# R7FA8M1AH register map
Vendor: Renesas; Series: RA8; File version: 1.2
CPU: CM85 r0p0, little endian, MPU, FPU, VTOR, 4 interrupt priority bits
Registers are 32-bit, read-write, reset 0x0 unless marked. A register's access mark holds for its fields unless they carry their own. Offsets are from the block's base; [hi:lo] are bit positions; {n}, {i} and the like mark numbered series; 'fields as' and 'values as' point back to an identical list.

## SPI0 — Serial Peripheral Interface 0
Base 0x4035C000
Same registers: SPI1 0x4035C100, SPI0_NS 0x5035C000, SPI1_NS 0x5035C100
0x00 SPDR — RSPI Data Register
  [31:0] SPD — SPDR is the interface with the buffers that hold data for transmission and reception by the SPI.When accessing in word (SPDCR.SPBYT=0 and SPDCR.SPLW=1), access SPDR.
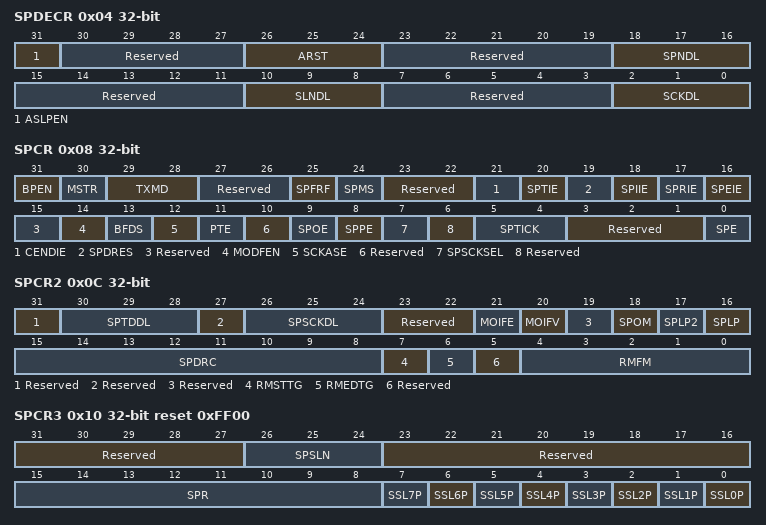
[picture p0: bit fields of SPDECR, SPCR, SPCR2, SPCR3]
0x04 SPDECR — RSPI Delay Control Register
  [31] ASLPEN — Receive sampling timing loopback adjustment function selection bit(Private)
    0=Receive sampling timing loopback adjustment function enabled; 1=Receive sampling timing loopback adjustment function disabled
  [30:27] Reserved — These bits are read as 0000. The write value should be 0000.
  [26:24] ARST — Adjust receive sampling by delaying 0 to 4 TCLK from the center of bit.
    0=0 TCLK delay; 1=1 TCLK delay; 2=2 TCLK delay; 3=3TCLK delay; {v}={v} TCLK delay (v=4..7)
  [23:19] Reserved — These bits are read as 00000. The write value should be 00000.
  [18:16] SPNDL — SPI Next-Access Delay Setting
    {v}={v+1} RSPCK + 2 TCLK (v=0..7)
  [15:11] Reserved — These bits are read as 00000. The write value should be 00000.
  [10:8] SLNDL — SSL Negation Delay Setting
    {v}={v+1} RSPCK (v=0..7)
  [7:3] Reserved — These bits are read as 00000. The write value should be 00000.
  [2:0] SCKDL — RSPCK Delay setting bit
    {v}={v+1} RSPCK (v=0..7)
0x08 SPCR — RSPI Control Register
  [31] BPEN — Synchronization circuit bypass enable bit
    0=Non-bypass; 1=Bypass
  [30] MSTR — RSPI Master/Slave Mode Select
    0=Select slave mode; 1=Select master mode
  [29:28] TXMD — Communications Operating Mode Select
    0=Transmission / reception serial communication; 1=Transmission only
  [27:26] Reserved — These bits are read as 00. The write value should be 00.
  [25] SPFRF — RSPI frame format selection bit(Initial value: 1'b0)
    0=Motorola SPI; 1=TI SSP "
  [24] SPMS — RSPI Mode Select
    0=Select RSPI operation (4-wire method); 1=Select clock synchronous operation (3-wire method)
  [23:22] Reserved — These bits are read as 00. The write value should be 00.
  [21] CENDIE — RSPI Communication End Interrupt Enable
    0=Disable communication end interrupt request; 1=Enable communication end interrupt request
  [20] SPTIE — Transmit Buffer Empty Interrupt Enable
    0=Disable transmit buffer empty interrupt requests; 1=Enable transmit buffer empty interrupt requests
  [19] SPDRES — Receive data ready error select bit
    0=Receive data full interrupt; 1=Error interrupt
  [18] SPIIE — RSPI Idle Interrupt Enable
    0=Disable idle interrupt requests; 1=Enable idle interrupt requests
  [17] SPRIE — RSPI Receive Buffer Full Interrupt Enable
    0=Disable RSPI receive buffer full interrupt requests; 1=Enable RSPI receive buffer full interrupt requests
  [16] SPEIE — RSPI Error Interrupt Enable
    0=Disable RSPI error interrupt requests; 1=Enable RSPI error interrupt requests
  [15] Reserved — This bit is read as 0. The write value should be 0.
  [14] MODFEN — Mode Fault Error Detection Enable
    0=Disable detection of mode fault errors; 1=Enable detection of mode fault errors
  [13] BFDS — Delay Selection Bit between frames for Burst Transfer
    0=Delay (RSPCK delay, SSL negation delay and next-access delay) between frames is inserted in burst transfer; 1=Delay between frames is not inserted in burst transfer
  [12] SCKASE — RSPCK Auto-Stop Function Enable
    0=Disable RSPCK auto-stop function; 1=Enable RSPCK auto-stop function
  [11] PTE — Parity Self-Testing
    0=Disable self-diagnosis function of the parity circuit; 1=Enable self-diagnosis function of the parity circuit
  [10] Reserved — This bit is read as 0. The write value should be 0.
  [9] SPOE — Parity Mode
    0=Select even parity for transmission and reception; 1=Select odd parity for transmission and reception
  [8] SPPE — Parity Enable
    0=Do not add parity bit to transmit data and do not check parity bit of receive data; 1=Add parity bit to transmit data and check parity bit of receive data
  [7] SPSCKSEL — RSPI master receive clock select bit
    0=MRIOCLK selection (analog delay adjustment); 1=MRCLK selection (digital delay adjustment)
  [6] Reserved — This bit is read as 0. The write value should be 0.
  [5:4] SPTICK — TI SSP clock format control bit
    0=Default (no additional clock is output after the last data); 1=Output 1RSPCK additionally after the last data; 3=Output ∞ RSPCK additionally after the last dataSetting other than above is prohibited
  [3:1] Reserved — These bits are read as 000. The write value should be 000.
  [0] SPE read-modifies — RSPI Function Enable
    0=Disable RSPI function; 1=Enable RSPI function
0x0C SPCR2 — RSPI Control Register 2
  [31] Reserved — This bit is read as 0. The write value should be 0.
  [30:28] SPTDDL — RSPI transmit data delay setting bit
    0=No delay; 1=Enter the delay according to the product specifications; {v}=↑ (v=2..7)
  [27] Reserved — This bit is read as 0. The write value should be 0.
  [26:24] SPSCKDL — RSPI master receive clock analog delay setting bit
    values as SPTDDL
  [23:22] Reserved — These bits are read as 00. The write value should be 00.
  [21] MOIFE — MOSI Idle Value Fixing Enable
    0=Set MOSI output value to equal final data from previous transfer; 1=Set MOSI output value to equal value set in the MOIFV bit
  [20] MOIFV — MOSI Idle Fixed Value
    0=Set level output on MOSIn pin during MOSI idling to correspond to low; 1=Set level output on MOSIn pin during MOSI idling to correspond to high
  [19] Reserved — This bit is read as 0. The write value should be 0.
  [18] SPOM — RSPI Output Pin Mode Select
    0=CMOS output; 1=Open-drain output
  [17] SPLP2 — RSPI Loopback 2
    0=Normal mode; 1=Loopback mode (data is not inverted for transmission)
  [16] SPLP — RSPI Loopback
    0=Normal mode; 1=Loopback mode (data is inverted for transmission)
  [15:8] SPDRC — RSPI Receive data ready detection adjustment bit
  [7] RMSTTG wo — Reception only master start bit
    0=Reception only master and reception stopped; 1=Reception only starts with master(1 is writable only for receive master)
  [6] RMEDTG wo — Reception only master end bit
    values as RMSTTG
  [5] Reserved — This bit is read as 0. The write value should be 0.
  [4:0] RMFM — Receive-only master frame processing count setting bit
0x10 SPCR3 reset 0xFF00 — RSPI Control Register 3
  [31:27] Reserved — These bits are read as 00000. The write value should be 00000.
  [26:24] SPSLN — RSPI sequence length setting bit
    0=Sequence Length 1 SPDMDx x = 0->0->; 1=Sequence Length 2 SPDMDx x = 0->1->0->; 2=Sequence Length 3 SPDMDx x = 0->1->2->0->; 3=Sequence Length 4 SPDMDx x = 0->1->2->3->0->; 4=Sequence Length 5 SPDMDx x = 0->1->2->3->4->0->; 5=Sequence Length 6 SPDMDx x = 0->1->2->3->4->5->0->; 6=Sequence Length 7 SPDMDx x = 0->1->2->3->4->5->6->0->; 7=Sequence Length 8 SPDMDx x = 0->1->2->3->4->5->6->7->0->
  [23:16] Reserved — These bits are read as 00000000. The write value should be 00000000.
  [15:8] SPR — SPBR sets the bit rate in master mode.
  [n] SSL{n}P (n=0..7) — SSL{n} Signal Polarity Setting
    0=Set SSL{n} signal to active low; 1=Set SSL{n} signal to active high
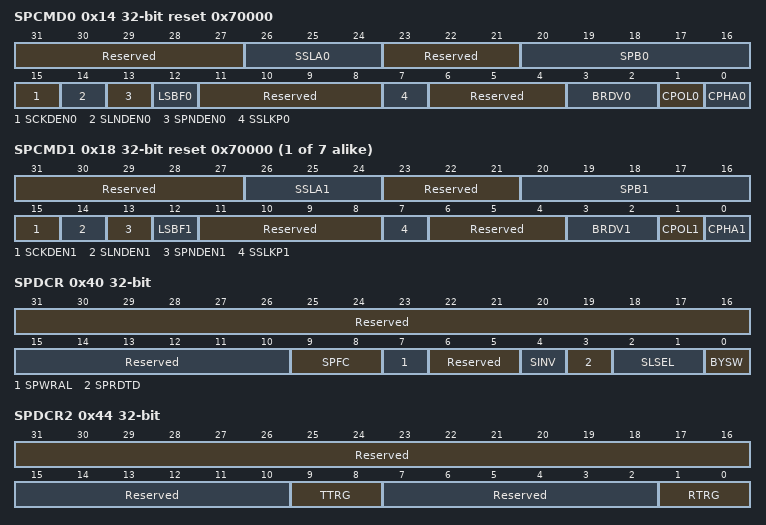
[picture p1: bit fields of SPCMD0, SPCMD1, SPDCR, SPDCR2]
0x14 SPCMD0 reset 0x70000 — RSPI Command Register 0
  [31:27] Reserved — These bits are read as 00000. The write value should be 00000.
  [26:24] SSLA0 — SSL Signal Assertion Setting
    {v}=SSL{v} (v=0..7)
  [23:21] Reserved — These bits are read as 000. The write value should be 000.
  [20:16] SPB0 — RSPI data length setting bit
    0=~ 00010: Setting prohibited(If set, the same operation as 00011); 3=4bit; 4=5bit; 5=6bit; 30=31bit; 31=32bit
  [15] SCKDEN0 — RSPCK Delay Setting Enable
    0=Motolora SPI: RSPCK delay is 1RSPCK; 1=RSPCK delay is the value of the RSPCK delay register (SPCKD).Setting value
  [14] SLNDEN0 — SSL Negation Delay Setting Enable
    0=Select SSL negation delay of 1 RSPCK; 1=Select SSL negation delay equal to the setting in the SPI Slave Select Negation Delay Register (SSLND)
  [13] SPNDEN0 — RSPI Next-Access Delay Enable
    0=Select next-access delay of 1 RSPCK + 2 PCLK; 1=Select next-access delay equal to the setting in the SPI Next-Access Delay Register (SPND)
  [12] LSBF0 — RSPI LSB First bit
    0=MSB first; 1=LSB first
  [11:8] Reserved — These bits are read as 0000. The write value should be 0000.
  [7] SSLKP0 — SSL Signal Level Keeping
    0=Negate all SSL signals on completion of transfer; 1=Keep SSL signal level from the end of transfer until the beginning of the next access
  [6:4] Reserved — These bits are read as 000. The write value should be 000.
  [3:2] BRDV0 — Bit Rate Division Setting
    0=Base bit rate; 1=Base bit rate divided by 2; 2=Base bit rate divided by 4; 3=Base bit rate divided by 8
  [1] CPOL0 — RSPCK Polarity Setting
    0=Set RSPCK low during idle; 1=Set RSPCK high during idle
  [0] CPHA0 — RSPCK Phase Setting
    0=Select data sampling on leading edge, data change on trailing edge; 1=Select data change on leading edge, data sampling on trailing edge
{0x14+4i} SPCMD{i} reset 0x70000 (i=1..7) — RSPI Command Register {i}
  [31:27] Reserved — These bits are read as 00000. The write value should be 00000.
  [26:24] SSLA{i} — SSL Signal Assertion Setting
    {v}=SSL{v} (v=0..7)
  [23:21] Reserved — These bits are read as 000. The write value should be 000.
  [20:16] SPB{i} — RSPI data length setting bit
    values as SPCMD0.SPB0
  [15] SCKDEN{i} — RSPCK Delay Setting Enable
    0=Select RSPCK delay of 1RSPCK; 1=Select RSPCK delay equal to the setting in the SPI Clock Delay Register (SPCKD)
  [14] SLNDEN{i} — SSL Negation Delay Setting Enable
    values as SPCMD0.SLNDEN0
  [13] SPNDEN{i} — RSPI Next-Access Delay Enable
    values as SPCMD0.SPNDEN0
  [12] LSBF{i} — RSPI LSB First bit
    0=MSB first; 1=LSB first
  [11:8] Reserved — These bits are read as 0000. The write value should be 0000.
  [7] SSLKP{i} — SSL Signal Level Keeping
    values as SPCMD0.SSLKP0
  [6:4] Reserved — These bits are read as 000. The write value should be 000.
  [3:2] BRDV{i} — Bit Rate Division Setting
    values as SPCMD0.BRDV0
  [1] CPOL{i} — RSPCK Polarity Setting
    0=Set RSPCK low during idle; 1=Set RSPCK high during idle
  [0] CPHA{i} — RSPCK Phase Setting
    values as SPCMD0.CPHA0
0x40 SPDCR — RSPI Data Control Register
  [31:16] Reserved — These bits are read as 0000000000000000. The write value should be 0000000000000000.
  [15:10] Reserved — These bits are read as 000000. The write value should be 000000.
  [9:8] SPFC — Frame number setting bit
    0=1 frame; 1=2 frames; 14=15 frame; 15=16 frames
  [7] SPWRAL — RSPI write test mode
    0=Data is stored in one buffer by one writing access to SPDR; 1=Data is stored in all buffers by one writing access to SPDR
  [6:5] Reserved — These bits are read as 00. The write value should be 00.
  [4] SINV — Serial data invert
    0=Not invert serial data; 1=Invert serial data
  [3] SPRDTD — RSPI Receive/Transmit Data Select
    0=Read SPDR/SPDR_HA/SPDR_BY values from receive buffer; 1=Read SPDR/SPDR_HA/SPDR_BY values from transmit buffer, but only if the transmit buffer is empty
  [2:1] SLSEL — SSl Pin Output Specification(In the multi master mode (MODFEN=1), SSL0 (output) is disabled.)
    0=SSL0(output) is enabled / SSL1(output) is enabled / SSL2-7(Output) is enabled; 1=SSL0(output) is enabled / SSL1(output) is disabled / SSL2-7(Output) is disabled; 2=SSL0(output) is enabled / SSL1(output) is enabled / SSL2-7(Output) is disabled; 3=Setting Prohibited
  [0] BYSW — Byte Swap Operating Mode Select
    0=Byte Swap OFF; 1=Byte Swap ON
0x44 SPDCR2 — RSPI Data Control Register 2
  [31:16] Reserved — These bits are read as 0000000000000000. The write value should be 0000000000000000.
  [15:10] Reserved — These bits are read as 000000. The write value should be 000000.
  [9:8] TTRG — Transmission FIFO threshold setting bit
    {v}=Threshold {v+1} (v=0..3)
  [7:2] Reserved — These bits are read as 000000. The write value should be 000000.
  [1:0] RTRG — Receive FIFO threshold setting bit
    {v}=Threshold {v+1} (v=0..3)
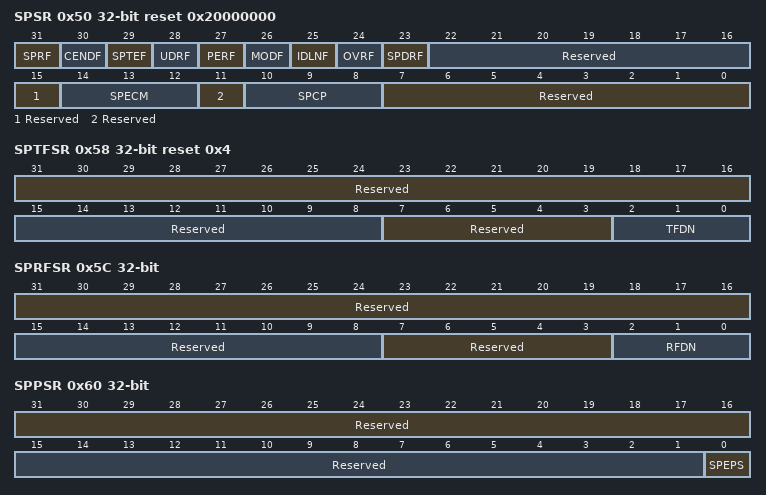
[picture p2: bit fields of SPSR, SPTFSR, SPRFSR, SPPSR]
0x50 SPSR ro reset 0x20000000 — RSPI Status Register
  [31] SPRF — Receive buffer full flag(Initial value: 1'b0)
    0=No valid data in the receive buffer; 1=Valid data in the receive buffer
  [30] CENDF — Communication complete flag(Initial value: 1'b0)
    0=SPI is not communicating or communicating; 1=SPI communication completed
  [29] SPTEF — Send bufferEmpty flag(Initial value: 1'b0)
    0=Data is in the transmit buffer; 1=No data is in the transmit buffer
  [28] UDRF — Underrun Error Flag(This bit is invalid when MODF flag is 0.)
    0=-: No mode fault error or underrun error; 2=Mode fault error occurred; 3=Underrun error occurred
  [27] PERF — Parity error flag(Initial value: 1'b0)
    0=No parity error occurred; 1=Parity error occurred
  [26] MODF — Mode fault error(Initial value: 1'b0)
    0=No mode fault or underrun error occurred; 1=Mode fault error or underrun error occurred
  [25] IDLNF — RSPI Idle Flag
    0=RSPI is in the idle state; 1=RSPI is in the transfer state
  [24] OVRF — Overrun error flag(Initial value: 1'b0)
    0=No overrun error occurred; 1=Overrun error occurred
  [23] SPDRF — Receive data delay flag
    0=It is Receiving now or Rx FIFO is read all data after completed reception normally; 1=Receive data is less than threshold and Next data is not received fixed period
  [22:16] Reserved — These bits are read as 0000000.
  [15] Reserved — This bit is read as 0.
  [14:12] SPECM — RSPI Error Command
    {v}=SPCMD{v} (v=0..7)
  [11] Reserved — This bit is read as 0.
  [10:8] SPCP — RSPI Command Pointer
    {v}=SPCMD{v} (v=0..7)
  [7:0] Reserved — These bits are read as 00000000.
0x58 SPTFSR ro reset 0x4 — RSPI transmit FIFO status register
  [31:16] Reserved — These bits are read as 0000000000000000.
  [15:8] Reserved — These bits are read as 00000000.
  [7:3] Reserved — These bits are read as 00000.
  [2:0] TFDN — Transmit FIFO data empty stage indication bit
    {v}=Empty stage number {v} (v=0..4)
0x5C SPRFSR ro — RSPI receive FIFO status register
  [31:16] Reserved — These bits are read as 0000000000000000.
  [15:8] Reserved — These bits are read as 00000000.
  [7:3] Reserved — These bits are read as 00000.
  [2:0] RFDN — Receive FIFO data storage stage number indication bit
    {v}=Empty stage number {v} (v=0..4)
0x60 SPPSR ro — RSPI Poling status regster
  [31:16] Reserved — These bits are read as 0000000000000000.
  [15:1] Reserved — These bits are read as 000000000000000.
  [0] SPEPS — SPE poling status regster
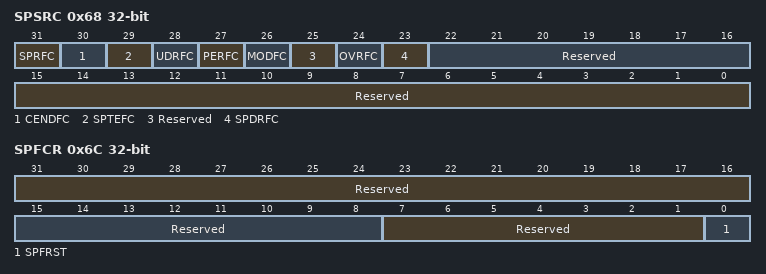
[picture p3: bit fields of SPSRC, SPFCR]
0x68 SPSRC — RSPI Status Clear Register
  [31] SPRFC wo — Clear receive buffer full flag(Initial value: 1'b0)
  [30] CENDFC wo — Clear communication complete flag(Initial value: 1'b0)
  [29] SPTEFC wo — Send bufferEmpty flag clear(Initial value: 1'b0)
  [28] UDRFC wo — Underrun error flag clear(Initial value: 1'b0)
  [27] PERFC wo — Clear parity error flag(Initial value: 1'b0)
  [26] MODFC wo — Mode fault error clear(Initial value: 1'b0)
  [25] Reserved — This bit is read as 0. The write value should be 0.
  [24] OVRFC wo — Clear overrun error flag(Initial value: 1'b0)
  [23] SPDRFC wo — Rx data ready flag clear bit
  [22:16] Reserved — These bits are read as 0000000. The write value should be 0000000.
  [15:0] Reserved — These bits are read as 0000000000000000. The write value should be 0000000000000000.
0x6C SPFCR — RSPI FIFO clear register
  [31:16] Reserved — These bits are read as 0000000000000000. The write value should be 0000000000000000.
  [15:8] Reserved — These bits are read as 00000000. The write value should be 00000000.
  [7:1] Reserved — These bits are read as 0000000. The write value should be 0000000.
  [0] SPFRST wo — RSPI FIFO clear bit
